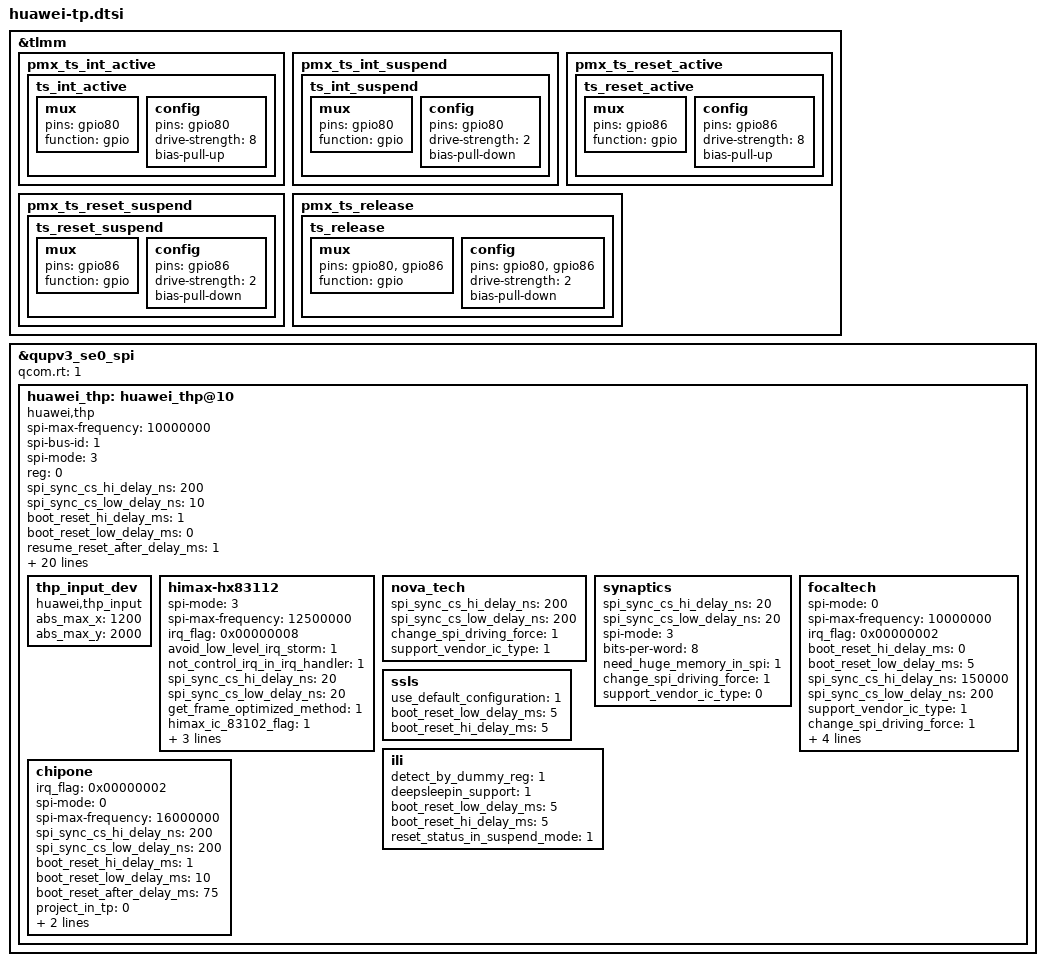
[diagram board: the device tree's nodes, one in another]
/* touch panel config */
&tlmm {
	pmx_ts_int_active {
		ts_int_active: ts_int_active {
			mux {
				pins = "gpio80";
				function = "gpio";
			};

			config {
				pins = "gpio80";
				drive-strength = <8>;
				bias-pull-up;
			};
		};
	};

	pmx_ts_int_suspend {
		ts_int_suspend: ts_int_suspend {
			mux {
				pins = "gpio80";
				function = "gpio";
			};

			config {
				pins = "gpio80";
				drive-strength = <2>;
				bias-pull-down;
			};
		};
	};

	pmx_ts_reset_active {
		ts_reset_active: ts_reset_active {
			mux {
				pins = "gpio86";
				function = "gpio";
			};

			config {
				pins = "gpio86";
				drive-strength = <8>;
				bias-pull-up;
			};
		};
	};

	pmx_ts_reset_suspend {
		ts_reset_suspend: ts_reset_suspend {
			mux {
				pins = "gpio86";
				function = "gpio";
			};

			config {
				pins = "gpio86";
				drive-strength = <2>;
				bias-pull-down;
			};
		};
	};

	pmx_ts_release {
		ts_release: ts_release {
			mux {
				pins = "gpio80", "gpio86";
				function = "gpio";
			};

			config {
				pins = "gpio80", "gpio86";
				drive-strength = <2>;
				bias-pull-down;
			};
		};
	};
};

&qupv3_se0_spi {
	status = "ok";

	#address-cells = <1>;
	#size-cells = <0>;
	qcom.rt = <1>;
	huawei_thp: huawei_thp@10 {
		compatible = "huawei,thp";
		/* SPI Config */
		spi-max-frequency = <10000000>;
		spi-bus-id = <1>;
		spi-mode = <3>;
		reg = <0>;
		spi_sync_cs_hi_delay_ns = <200>;
		spi_sync_cs_low_delay_ns = <10>;

		/* Timing */
		boot_reset_hi_delay_ms = <1>;
		boot_reset_low_delay_ms = <0>;
		resume_reset_after_delay_ms = <1>;
		suspend_reset_after_delay_ms = <1>;
		use_mdelay = <1>;

		/* GPIO Config */
		interrupt-parent = <&tlmm>;
		interrupts = <80 0>;
		rst_gpio = <&tlmm 86 0x00>;
		irq_gpio = <&tlmm 80 0x00>;
		cs_gpio = <&tlmm 3 0x00>;
		early_suspend_delay_ms = <250>;
		wait_afe_screen_on_support = <1>;

		/* Feature Config */
		pt_station_test = <1>;
		hide_product_info_en = <1>;
		support_vendor_ic_type = <1>;
		supported_charger = <1>;
		aptouch_daemon_version = <3>;
		use_thp_queue = <1>;
		support_gesture_mode = <1>;
		lcd_esd_event_upload = <1>;
		lcd_gesture_mode_support = <1>;
		need_enable_irq_wake = <1>;
		need_huge_memory_in_spi = <1>;
		thp_input_dev {
			compatible = "huawei,thp_input";
			abs_max_x = <1200>;
			abs_max_y = <2000>;
		};
		himax-hx83112 {
			spi-mode = <3>;
			spi-max-frequency = <12500000>;
			irq_flag = <0x00000008>;
			avoid_low_level_irq_storm = <1>;
			not_control_irq_in_irq_handler = <1>;
			spi_sync_cs_hi_delay_ns = <20>;
			spi_sync_cs_low_delay_ns = <20>;
			get_frame_optimized_method =<1>;
			himax_ic_83102_flag = <1>;
			himax_ic_83102_no_flash = <1>;
			himax_ic_hispeed_support = <1>;
			himax_gesture_need_lcd_rst = <1>;
		};
		nova_tech {
			spi_sync_cs_hi_delay_ns = <200>;
			spi_sync_cs_low_delay_ns = <200>;
			change_spi_driving_force = <1>;
			support_vendor_ic_type = <1>;
		};
		synaptics {
			spi_sync_cs_hi_delay_ns = <20>;
			spi_sync_cs_low_delay_ns = <20>;
			spi-mode = <3>;
			bits-per-word = <8>;
			need_huge_memory_in_spi = <1>;
			change_spi_driving_force = <1>;
			support_vendor_ic_type = <0>;
		};
		focaltech {
			spi-mode = <0>;
			spi-max-frequency = <10000000>;
			irq_flag = <0x00000002>;
			boot_reset_hi_delay_ms = <0>;
			boot_reset_low_delay_ms = <5>;
			spi_sync_cs_hi_delay_ns = <150000>;
			spi_sync_cs_low_delay_ns = <200>;
			support_vendor_ic_type = <1>;
			change_spi_driving_force = <1>;
			reset_status_in_suspend_mode = <0>;
			need_set_reset_gpio_high = <1>;
			lcd_need_get_afe_status = <0>;
			need_enable_irq_wake = <1>;
		};
		ssls {
			use_default_configuration = <1>;
			boot_reset_low_delay_ms = <5>;
			boot_reset_hi_delay_ms = <5>;
		};
		ili {
			detect_by_dummy_reg = <1>;
			deepsleepin_support = <1>;
			boot_reset_low_delay_ms = <5>;
			boot_reset_hi_delay_ms = <5>;
			reset_status_in_suspend_mode = <1>;
		};
		chipone {
			irq_flag = <0x00000002>;
			spi-mode = <0>;
			spi-max-frequency = <16000000>;
			spi_sync_cs_hi_delay_ns = <200>;
			spi_sync_cs_low_delay_ns = <200>;
			boot_reset_hi_delay_ms = <1>;
			boot_reset_low_delay_ms = <10>;
			boot_reset_after_delay_ms = <75>;
			project_in_tp = <0>;
			aod_support_on_tddi = <0>;
			support_vendor_ic_type = <3>;
		};
	};
};
